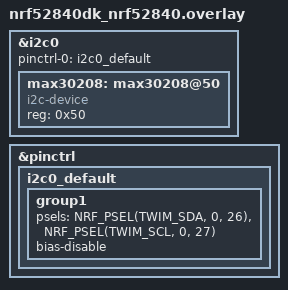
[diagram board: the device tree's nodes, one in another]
&i2c0 {
    status = "okay";
    pinctrl-0 = <&i2c0_default>;
    max30208: max30208@50 {
        compatible = "i2c-device";
        status = "okay";
        reg = <0x50>;
    };
};

&pinctrl {
    i2c0_default: i2c0_default {
        group1 {
            psels = <NRF_PSEL(TWIM_SDA, 0, 26)>,
                    <NRF_PSEL(TWIM_SCL, 0, 27)>;
            bias-disable;
        };
    };
};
